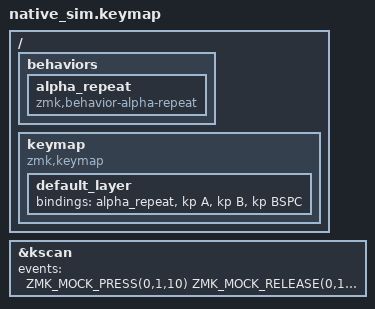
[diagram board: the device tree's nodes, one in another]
#include <behaviors.dtsi>
#include <dt-bindings/zmk/keys.h>
#include <dt-bindings/zmk/kscan_mock.h>

/ {
    behaviors {
        alpha_repeat: alpha_repeat {
            compatible = "zmk,behavior-alpha-repeat";
            #binding-cells = <0>;
        };
    };

    keymap {
        compatible = "zmk,keymap";

        default_layer {
            bindings = <&alpha_repeat &kp A &kp B &kp BSPC>;
        };
    };
};

&kscan {
    events = <
        ZMK_MOCK_PRESS(0,1,10)
        ZMK_MOCK_RELEASE(0,1,10)
        ZMK_MOCK_PRESS(1,0,10)
        ZMK_MOCK_RELEASE(1,0,10)
        ZMK_MOCK_PRESS(1,1,10)
        ZMK_MOCK_RELEASE(1,1,10)
        ZMK_MOCK_PRESS(0,0,10)
        ZMK_MOCK_RELEASE(0,0,10)
    >;
};
